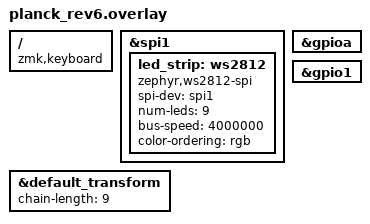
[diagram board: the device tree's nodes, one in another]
/ {
    compatible = "zmk,keyboard";
};

&spi1 {
    status = "okay";

    led_strip: ws2812 {
        compatible = "zephyr,ws2812-spi";
        spi-dev = <&spi1>;
        num-leds = <9>;
        bus-speed = <4000000>;
        color-ordering = <rgb>;
    };
};

&gpioa {
    status = "okay";
};

&gpio1 {
    status = "okay";
};

&default_transform {
    chain-length = <9>;
};
